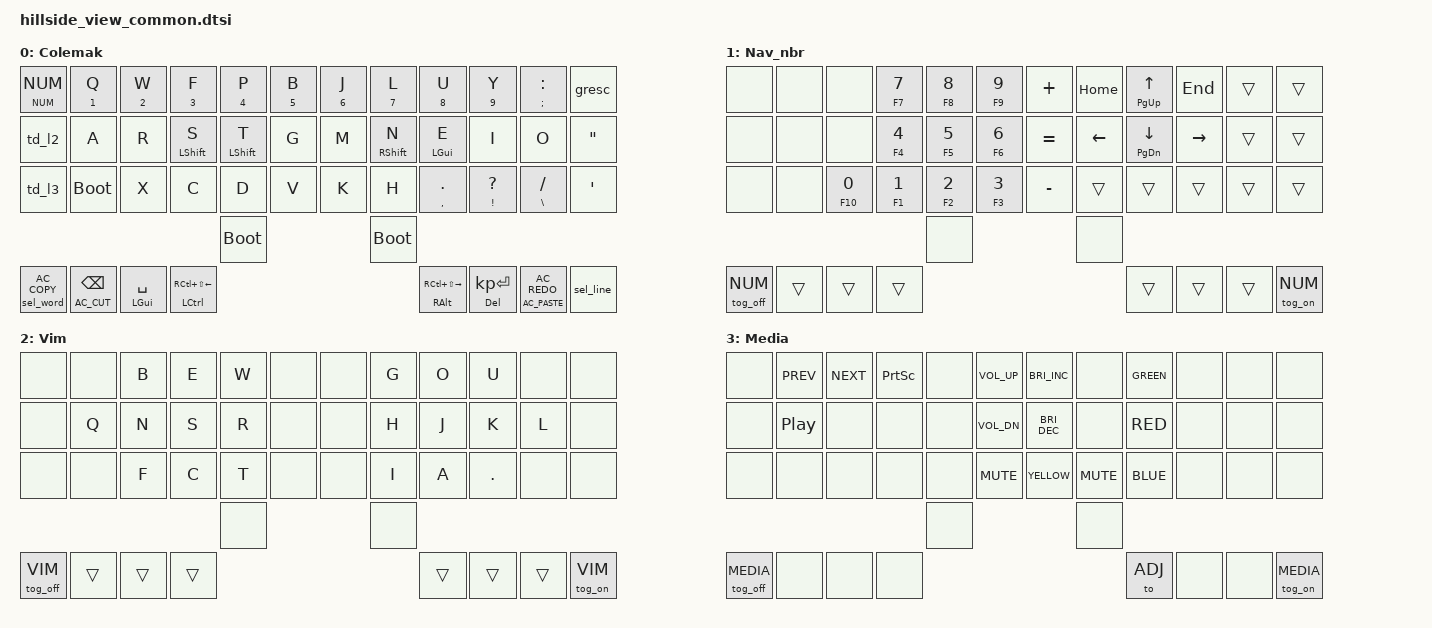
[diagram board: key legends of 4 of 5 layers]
#include <behaviors/studio_unlock.dtsi>
#include <behaviors.dtsi>
#include <dt-bindings/zmk/bt.h>
#include <dt-bindings/zmk/ext_power.h>
#include <dt-bindings/zmk/keys.h>
#include <dt-bindings/zmk/outputs.h>
#include <dt-bindings/zmk/rgb.h>

// Layer definitions
#define DEF 0
#define NUM 1
#define VIM 2
#define MEDIA 3
#define ADJ 4
#define GAME 5

// MS definitions
#define COMBO_TERM 30
#define TAPPING_TERM 250
#define QUICK_TAP_TERM 175
#define ADAPTIVE_KEY_TIMEOUT 2000

&mt {
    tapping-term-ms = <TAPPING_TERM>;
    quick-tap-ms = <QUICK_TAP_TERM>;
};

&lt {
    tapping-term-ms = <TAPPING_TERM>;
    quick-tap-ms = <QUICK_TAP_TERM>;
};

&sl {
    release-after-ms = <1500>;
    quick-release;
};

&sk {
    release-after-ms = <1500>;
    quick-release;
};

/ {
    conditional_layers {
        compatible = "zmk,conditional-layers";

        tri_layer {
            if-layers = <DEF NUM>;
            then-layer = <VIM>;
        };
    };

    macros {
        sel_word: sel_word {
            compatible = "zmk,behavior-macro-one-param";
            #binding-cells = <1>;
            bindings = <&kp LC(LEFT) &kp LS(LC(RIGHT))>;
            label = "SEL_WORD";
        };

        sel_line: sel_line {
            compatible = "zmk,behavior-macro";
            #binding-cells = <0>;
            bindings = <&kp HOME &kp LS(LC(END))>;
            label = "SEL_LINE";
        };
    };

    combos {
        compatible = "zmk,combos";

        caps {
            timeout-ms = <50>;
            key-positions = <16 19>;  // T and N (home row Caps Word)
            bindings = <&caps_word>;
            layers = <DEF>;
        };

        dollar {
            timeout-ms = <50>;
            key-positions = <3 8>;  // F and U
            bindings =<&kp DOLLAR>;
            layers = <DEF>;
        };

        lesser {
            timeout-ms = <50>;
            key-positions = <2 3>;  // W and F
            bindings =<&kp LESS_THAN>;
            layers = <DEF>;
        };

        lft_bracket {
            timeout-ms = <50>;
            key-positions = <3 4>;  // F and P
            bindings =<&kp LBKT>;
            layers = <DEF>;
        };

        pipe {
            timeout-ms = <50>;
            key-positions = <4 5>;  // P and B
            bindings =<&kp PIPE>;
            layers = <DEF>;
        };

        underscore {
            timeout-ms = <50>;
            key-positions = <6 7>;  // J AND L
            bindings =<&kp UNDERSCORE>;
            layers = <DEF>;
        };

        rg_bracket {
            timeout-ms = <50>;
            key-positions = <7 8>;  // L AND U
            bindings =<&kp RBKT>;
            layers = <DEF>;
        };

        greater {
            timeout-ms = <50>;
            key-positions = <8 9>;  // U and Y
            bindings =<&kp GREATER_THAN>;
            layers = <DEF>;
        };

        equal {
            timeout-ms = <50>;
            key-positions = <13 14>;  // A and R
            bindings =<&kp EQUAL>;
            layers = <DEF>;
        };

        plus {
            timeout-ms = <50>;
            key-positions = <14 15>;  // R and S
            bindings =<&kp PLUS>;
            layers = <DEF>;
        };

        lf_parenthesis {
            timeout-ms = <50>;
            key-positions = <15 16>;  // S and T
            bindings =<&kp LPAR>;
            layers = <DEF>;
        };

        hash {
            timeout-ms = <50>;
            key-positions = <16 17>;  // T and G
            bindings =<&kp HASH>;
            layers = <DEF>;
        };

        at {
            timeout-ms = <50>;
            key-positions = <18 19>;  // M and N
            bindings =<&kp AT>;
            layers = <DEF>;
        };

        rg_parenthesis {
            timeout-ms = <50>;
            key-positions = <19 20>;  // N and E
            bindings =<&kp RPAR>;
            layers = <DEF>;
        };

        minus {
            timeout-ms = <50>;
            key-positions = <20 21>;  // E and I
            bindings =<&kp MINUS>;
            layers = <DEF>;
        };

        asterisk {
            timeout-ms = <50>;
            key-positions = <21 22>;  // I and O
            bindings =<&kp ASTERISK>;
            layers = <DEF>;
        };

        lf_brace {
            timeout-ms = <50>;
            key-positions = <27 28>;  // C and D
            bindings =<&kp LBRC>;
            layers = <DEF>;
        };

        percent {
            timeout-ms = <50>;
            key-positions = <28 29>;  // D and V
            bindings =<&kp PRCNT>;
            layers = <DEF>;
        };

        caret {
            timeout-ms = <50>;
            key-positions = <30 31>;  // K and H
            bindings =<&kp CARET>;
            layers = <DEF>;
        };

        rg_brace {
            timeout-ms = <50>;
            key-positions = <31 32>;  // H and DOT
            bindings =<&kp RBRC>;
            layers = <DEF>;
        };

        ampersand {
            timeout-ms = <50>;
            key-positions = <32 33>;  // DOT and EXCLAM
            bindings =<&kp AMPERSAND>;
            layers = <DEF>;
        };

        cut {
            timeout-ms = <50>;
            key-positions = <7 8>;  // g AND o
            bindings =<&kp X>;
            layers = <VIM>;
        };

        delete {
            timeout-ms = <50>;
            key-positions = <8 9>;  // o AND u
            bindings =<&kp D>;
            layers = <VIM>;
        };

        paste {
            timeout-ms = <50>;
            key-positions = <19 20>;  // h AND j
            bindings =<&kp P>;
            layers = <VIM>;
        };

        yank {
            timeout-ms = <50>;
            key-positions = <20 21>;  // j AND k
            bindings =<&kp Y>;
            layers = <VIM>;
        };

        visual {
            timeout-ms = <50>;
            key-positions = <31 32>;  // i AND a
            bindings =<&kp V>;
            layers = <VIM>;
        };

        next-prev {
            timeout-ms = <50>;
            key-positions = <32 33>;  // a AND DOT
            bindings =<&kp COMMA>;
            layers = <VIM>;
        };
    };

    behaviors {
    
    // layer toggles
        tog_on: toggle_layer_on_only {
            compatible = "zmk,behavior-toggle-layer";
            #binding-cells = <1>;
            display-name = "Toggle Layer On";
            toggle-mode = "on";
        };

        tog_off: toggle_layer_off_only {
            compatible = "zmk,behavior-toggle-layer";
            #binding-cells = <1>;
            display-name = "Toggle Layer Off";
            toggle-mode = "off";
        };

    // Layer taps
        hlt: layer-tap-with-hold-preferred {
            compatible = "zmk,behavior-hold-tap";
            #binding-cells = <2>;
            tapping-term-ms = <TAPPING_TERM>;
            flavor = "balanced";
            quick-tap-ms = <QUICK_TAP_TERM>;
            bindings = <&mo>, <&kp>;
        };

        hls: layer-tap-with-stick-layer {
            compatible = "zmk,behavior-hold-tap";
            #binding-cells = <2>;
            tapping-term-ms = <TAPPING_TERM>;
            flavor = "tap-preferred";
            quick-tap-ms = <QUICK_TAP_TERM>;
            bindings = <&mo>, <&sl>;
        };

    // Hold-tap behaviors
        hsk: mod-tap-with-stick-key {
            compatible = "zmk,behavior-hold-tap";
            #binding-cells = <2>;
            tapping-term-ms = <TAPPING_TERM>;
            flavor = "hold-preferred";
            quick-tap-ms = <QUICK_TAP_TERM>;
            bindings = <&kp>, <&sk>;
        };

        htb: hold_tap_balanced {
            compatible = "zmk,behavior-hold-tap";
            label = "Hold Tap Balanced";
            #binding-cells = <2>;
            flavor = "balanced";
            tapping-term-ms = <TAPPING_TERM>;
            quick-tap-ms = <QUICK_TAP_TERM>;
            bindings = <&kp>, <&kp>;
        };

    // tap Dances
        td_l2: tap_dance_l2 {
            compatible = "zmk,behavior-tap-dance";
            #binding-cells = <0>;
            tapping-term-ms = <TAPPING_TERM>;
            bindings = <&hls VIM VIM>, <&kp TAB>;
        };

        td_l3: tap_dance_l3 {
            compatible = "zmk,behavior-tap-dance";
            #binding-cells = <0>;
            tapping-term-ms = <TAPPING_TERM>;
            bindings = <&hls MEDIA MEDIA>, <&kp TILDE>;
        };
    
    // Combo hold
        htcp: hold_tap_copy {
            compatible = "zmk,behavior-hold-tap";
            label = "Hold Tap";
            display-name = "Hold-Tap";
            #binding-cells = <2>;
            flavor = "tap-preferred";
            tapping-term-ms = <TAPPING_TERM>;
            quick-tap-ms = <QUICK_TAP_TERM>;
            bindings = <&sel_word>, <&kp>;
        };

    };

    keymap {
        compatible = "zmk,keymap";

        default_layer {
            display-name = "Colemak";
            bindings = <
    &hls NUM NUM    &htb N1 Q   &htb N2 W   &htb N3 F       &htb N4 P       &htb N5 B       &htb N6 J   &htb N7 L               &htb N8 U       &htb N9 Y          &htb SEMI COLON  &gresc
    &td_l2          &kp A       &kp R       &htb LSHIFT S   &htb LSHIFT T   &kp G           &kp M       &htb RSHIFT N           &htb LGUI E     &kp I              &kp O            &kp DQT
    &td_l3          &bootloader &kp X       &kp C           &kp D           &kp V           &kp K       &kp H                   &htb COMMA DOT  &htb EXCL QMARK    &htb BSLH FSLH   &kp SQT
                                                            &bootloader                                       &bootloader
    &htcp 0 C_AC_COPY           &htb C_AC_CUT BSPC          &htb LGUI SPACE &htb LCTRL RC(LS(LEFT))     &htb RALT RC(LS(RIGHT)) &htb DEL KP_ENTER &htb C_AC_PASTE C_AC_REDO           &sel_line
            >;

            sensor-bindings = <&inc_dec_kp PG_UP PG_DN &inc_dec_kp C_VOL_UP C_VOL_DN>;
        };

        num_layer {
            display-name = "Nav_nbr";
            bindings = <
    &none  &none  &none             &htb F7 N7  &htb F8 N8   &htb F9 N9         &kp PLUS    &kp HOME    &htb PG_UP UP    &kp END     &trans  &trans
    &none  &none  &none             &htb F4 N4  &htb F5 N5   &htb F6 N6         &kp EQUAL   &kp LEFT    &htb PG_DN DOWN  &kp RIGHT   &trans  &trans
    &none  &none  &htb F10 N0       &htb F1 N1  &htb F2 N2   &htb F3 N3         &kp MINUS   &trans      &trans          &trans      &trans  &trans
                                                &none                                       &none
                    &tog_off NUM    &trans      &trans      &trans              &trans      &trans      &trans          &tog_on NUM
            >;

            sensor-bindings = <&inc_dec_kp UP DOWN &inc_dec_kp C_NEXT C_PREV>;
        };

        vim_layer {
            display-name = "Vim";
            bindings = <
    &none   &none   &kp B   &kp E   &kp W   &none       &none   &kp G   &kp O   &kp U   &none  &none
    &none   &kp Q   &kp N   &kp S   &kp R   &none       &none   &kp H   &kp J   &kp K   &kp L  &none
    &none   &none   &kp F   &kp C   &kp T   &none       &none   &kp I   &kp A   &kp DOT &none  &none
                                    &none                       &none
            &tog_off VIM    &trans  &trans  &trans      &trans  &trans  &trans  &tog_on VIM
            >;

            sensor-bindings = <&inc_dec_kp UP DOWN &inc_dec_kp C_NEXT C_PREV>;
        };

        media_layer {
            display-name = "Media";
            bindings = <
    &none   &kp C_PREV  &kp C_NEXT  &kp PSCRN   &none   &kp C_VOL_UP        &kp C_BRI_INC   &none       &kp C_GREEN &none   &none   &none
    &none   &kp C_PP    &none       &none       &none   &kp C_VOL_DN        &kp C_BRI_DEC   &none       &kp C_RED   &none   &none   &none
    &none   &none       &none       &none       &none   &kp C_MUTE          &kp C_YELLOW    &kp K_MUTE  &kp C_BLUE  &none   &none   &none
                                                &none                                       &none
            &tog_off MEDIA          &none       &none   &none               &to ADJ         &none       &none       &tog_on MEDIA
            >;

            sensor-bindings = <&inc_dec_kp UP DOWN &inc_dec_kp C_NEXT C_PREV>;
        };

        adjust_layer {
            display-name = "Adjust";
            bindings = <
    &none       &bt BT_SEL 0    &bt BT_SEL 1    &bt BT_SEL 2    &bt BT_SEL 3    &none           &out OUT_USB    &out OUT_BLE    &none   &rgb_ug RGB_ON  &none   &none
    &none       &bt BT_DISC 0   &bt BT_DISC 1   &bt BT_DISC 2   &bt BT_DISC 3   &none           &none           &none           &none           &none           &none   &rgb_ug RGB_OFF &none   &none
    &bootloader &none           &none           &none           &none           &bt BT_CLR      &kp UNDER       &none           &none   &studio_unlock  &none   &bootloader
                                                                &none                                           &none
                &none    &none           &none           &none           &to DEF         &none           &none           &none
            >;

            sensor-bindings = <&inc_dec_kp UP DOWN &inc_dec_kp C_NEXT C_PREV>;
        };
    };
};
